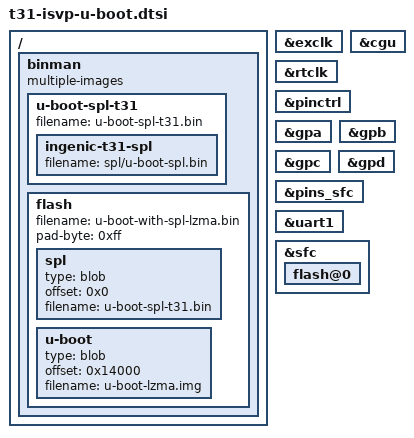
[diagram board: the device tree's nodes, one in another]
// SPDX-License-Identifier: GPL-2.0+
/*
 * Binman image description for the Ingenic ISVP-T31 SFC-NOR boot.
 *
 * The T31 mask ROM boots from SPI-NOR by reading a headered SPL at
 * flash offset 0, which then loads U-Boot proper from a fixed offset.
 * This builds both pieces with 'make':
 *
 *   u-boot-spl-t31.bin       : SPL with the finalized SFC-NOR boot
 *                              header (CRC7 + image length), bootable
 *                              standalone (equiv. to tools/mkt31spl.c).
 *   u-boot-with-spl-lzma.bin : headered SPL at offset 0 + LZMA U-Boot
 *                              at 0x14000 (CONFIG_SYS_SPI_U_BOOT_OFFS,
 *                              read by SPL_SPI_LOAD), trimmed
 *                              (no 0xff padding) - flash at offset 0;
 *                              erased flash already reads 0xff.
 */

/ {
	binman: binman {
		multiple-images;
	};
};

&binman {
	/*
	 * Standalone headered SPL: take the freshly built
	 * spl/u-boot-spl.bin through the T31 boot-header finalizer.
	 */
	u-boot-spl-t31 {
		filename = "u-boot-spl-t31.bin";

		ingenic-t31-spl {
			filename = "spl/u-boot-spl.bin";
		};
	};

	/*
	 * Combined SFC-NOR flash image: headered SPL at offset 0, LZMA
	 * U-Boot at 0x14000 = CONFIG_SYS_SPI_U_BOOT_OFFS (DM SPL ~48 KB /
	 * MAX_SIZE 0x13000; 0x14000 clears it with margin). Trimmed to the end of the
	 * last entry; erased flash reads 0xff so the rest of the chip
	 * is fine to leave alone after flashing at offset 0.
	 */
	flash {
		filename = "u-boot-with-spl-lzma.bin";
		pad-byte = <0xff>;

		spl {
			type = "blob";
			offset = <0x0>;
			filename = "u-boot-spl-t31.bin";
		};

		u-boot {
			type = "blob";
			offset = <0x14000>;
			filename = "u-boot-lzma.img";
		};
	};
};

/*
 * Tag the nodes the SPL needs - fixed clocks, CGU, pinctrl + gpio banks,
 * the SFC pin group, the console UART and the SFC + its flash - for all
 * boot phases, so fdtgrep keeps only these in the SPL device tree.
 * Without this the SPL DT pulls in every node and dm_autoprobe()
 * exhausts the early SPL malloc (spl_init() -> -ENOMEM).
 */
&exclk { bootph-all; };
&rtclk { bootph-all; };
&cgu { bootph-all; };
&pinctrl { bootph-all; };
&gpa { bootph-all; };
&gpb { bootph-all; };
&gpc { bootph-all; };
&gpd { bootph-all; };
&pins_sfc { bootph-all; };
&uart1 { bootph-all; };
&sfc {
	bootph-all;
	flash@0 {
		bootph-all;
	};
};
